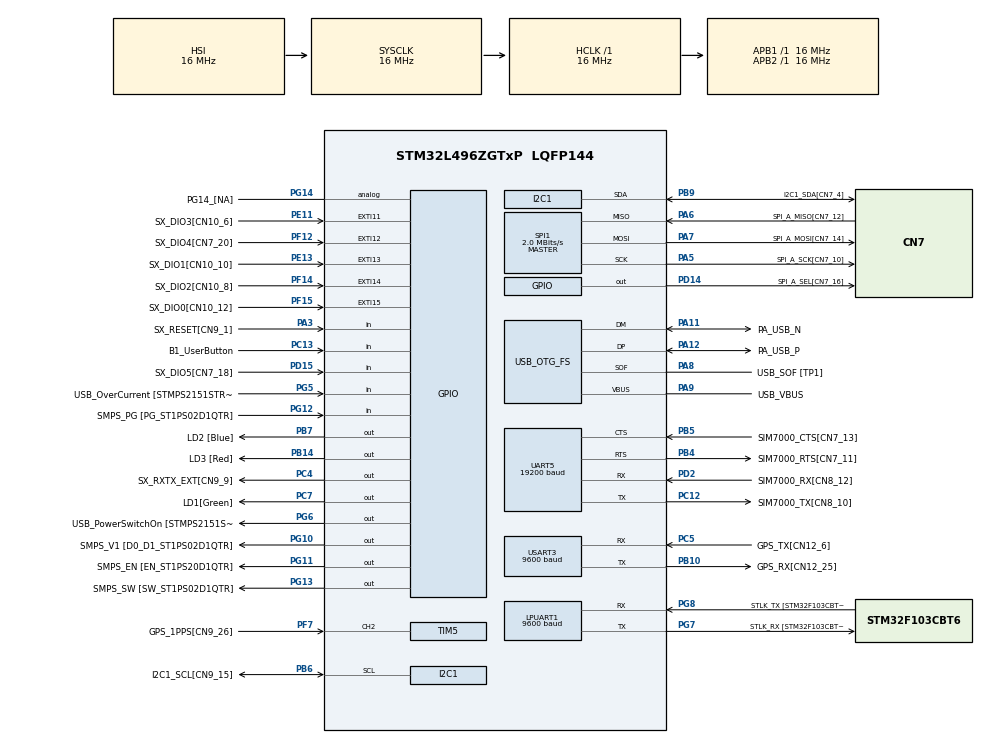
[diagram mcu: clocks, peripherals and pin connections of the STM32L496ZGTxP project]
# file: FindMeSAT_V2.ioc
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ADC1.Channel-0\#ChannelRegularConversion=ADC_CHANNEL_VREFINT
ADC1.Channel-1\#ChannelRegularConversion=ADC_CHANNEL_VBAT
ADC1.Channel-2\#ChannelRegularConversion=ADC_CHANNEL_TEMPSENSOR
ADC1.ClockPrescaler=ADC_CLOCK_ASYNC_DIV1
ADC1.ContinuousConvMode=DISABLE
ADC1.DMAContinuousRequests=DISABLE
ADC1.DiscontinuousConvMode=DISABLE
ADC1.EOCSelection=ADC_EOC_SEQ_CONV
ADC1.NbrOfConversion=3
ADC1.NbrOfConversionFlag=1
ADC1.OffsetNumber-0\#ChannelRegularConversion=ADC_OFFSET_NONE
ADC1.OffsetNumber-1\#ChannelRegularConversion=ADC_OFFSET_NONE
ADC1.OffsetNumber-2\#ChannelRegularConversion=ADC_OFFSET_NONE
ADC1.Overrun=ADC_OVR_DATA_OVERWRITTEN
ADC1.OversamplingMode=ENABLE
ADC1.Rank-0\#ChannelRegularConversion=1
ADC1.Rank-1\#ChannelRegularConversion=2
ADC1.Rank-2\#ChannelRegularConversion=3
ADC1.Ratio=ADC_OVERSAMPLING_RATIO_16
ADC1.RightBitShift=ADC_RIGHTBITSHIFT_NONE
ADC1.SamplingTime-0\#ChannelRegularConversion=ADC_SAMPLETIME_92CYCLES_5
ADC1.SamplingTime-1\#ChannelRegularConversion=ADC_SAMPLETIME_92CYCLES_5
ADC1.SamplingTime-2\#ChannelRegularConversion=ADC_SAMPLETIME_92CYCLES_5
ADC1.master=1
CRC.InputDataFormat=CRC_INPUTDATA_FORMAT_WORDS
Dma.ADC1.0.Direction=DMA_PERIPH_TO_MEMORY
Dma.ADC1.0.Instance=DMA1_Channel1
Dma.ADC1.0.MemDataAlignment=DMA_MDATAALIGN_HALFWORD
Dma.ADC1.0.MemInc=DMA_MINC_ENABLE
Dma.ADC1.0.Mode=DMA_CIRCULAR
Dma.ADC1.0.PeriphDataAlignment=DMA_PDATAALIGN_HALFWORD
Dma.ADC1.0.PeriphInc=DMA_PINC_DISABLE
Dma.ADC1.0.Priority=DMA_PRIORITY_LOW
Dma.LPUART_RX.8.Direction=DMA_PERIPH_TO_MEMORY
Dma.LPUART_RX.8.Instance=DMA2_Channel7
Dma.LPUART_RX.8.MemDataAlignment=DMA_MDATAALIGN_BYTE
Dma.LPUART_RX.8.MemInc=DMA_MINC_ENABLE
Dma.LPUART_RX.8.Mode=DMA_NORMAL
Dma.LPUART_RX.8.PeriphDataAlignment=DMA_PDATAALIGN_BYTE
Dma.LPUART_RX.8.PeriphInc=DMA_PINC_DISABLE
Dma.LPUART_RX.8.Priority=DMA_PRIORITY_HIGH
Dma.LPUART_TX.7.Direction=DMA_MEMORY_TO_PERIPH
Dma.LPUART_TX.7.Instance=DMA2_Channel6
Dma.LPUART_TX.7.MemDataAlignment=DMA_MDATAALIGN_BYTE
Dma.LPUART_TX.7.MemInc=DMA_MINC_ENABLE
Dma.LPUART_TX.7.Mode=DMA_NORMAL
Dma.LPUART_TX.7.PeriphDataAlignment=DMA_PDATAALIGN_BYTE
Dma.LPUART_TX.7.PeriphInc=DMA_PINC_DISABLE
Dma.LPUART_TX.7.Priority=DMA_PRIORITY_HIGH
Dma.Request0=ADC1
Dma.Request1=SPI1_TX
Dma.Request2=SPI1_RX
Dma.Request3=USART3_TX
Dma.Request4=USART3_RX
Dma.Request5=UART5_TX
Dma.Request6=UART5_RX
Dma.Request7=LPUART_TX
Dma.Request8=LPUART_RX
Dma.SPI1_RX.2.Direction=DMA_PERIPH_TO_MEMORY
Dma.SPI1_RX.2.Instance=DMA2_Channel3
Dma.SPI1_RX.2.MemDataAlignment=DMA_MDATAALIGN_BYTE
Dma.SPI1_RX.2.MemInc=DMA_MINC_ENABLE
Dma.SPI1_RX.2.Mode=DMA_NORMAL
Dma.SPI1_RX.2.PeriphDataAlignment=DMA_PDATAALIGN_BYTE
Dma.SPI1_RX.2.PeriphInc=DMA_PINC_DISABLE
Dma.SPI1_RX.2.Priority=DMA_PRIORITY_LOW
Dma.SPI1_TX.1.Direction=DMA_MEMORY_TO_PERIPH
Dma.SPI1_TX.1.Instance=DMA2_Channel4
Dma.SPI1_TX.1.MemDataAlignment=DMA_MDATAALIGN_BYTE
Dma.SPI1_TX.1.MemInc=DMA_MINC_ENABLE
Dma.SPI1_TX.1.Mode=DMA_NORMAL
Dma.SPI1_TX.1.PeriphDataAlignment=DMA_PDATAALIGN_BYTE
Dma.SPI1_TX.1.PeriphInc=DMA_PINC_DISABLE
Dma.SPI1_TX.1.Priority=DMA_PRIORITY_LOW
Dma.UART5_RX.6.Direction=DMA_PERIPH_TO_MEMORY
Dma.UART5_RX.6.Instance=DMA2_Channel2
Dma.UART5_RX.6.MemDataAlignment=DMA_MDATAALIGN_BYTE
Dma.UART5_RX.6.MemInc=DMA_MINC_ENABLE
Dma.UART5_RX.6.Mode=DMA_NORMAL
Dma.UART5_RX.6.PeriphDataAlignment=DMA_PDATAALIGN_BYTE
Dma.UART5_RX.6.PeriphInc=DMA_PINC_DISABLE
Dma.UART5_RX.6.Priority=DMA_PRIORITY_HIGH
Dma.UART5_TX.5.Direction=DMA_MEMORY_TO_PERIPH
Dma.UART5_TX.5.Instance=DMA2_Channel1
Dma.UART5_TX.5.MemDataAlignment=DMA_MDATAALIGN_BYTE
Dma.UART5_TX.5.MemInc=DMA_MINC_ENABLE
Dma.UART5_TX.5.Mode=DMA_NORMAL
Dma.UART5_TX.5.PeriphDataAlignment=DMA_PDATAALIGN_BYTE
Dma.UART5_TX.5.PeriphInc=DMA_PINC_DISABLE
Dma.UART5_TX.5.Priority=DMA_PRIORITY_HIGH
Dma.USART3_RX.4.Direction=DMA_PERIPH_TO_MEMORY
Dma.USART3_RX.4.Instance=DMA1_Channel3
Dma.USART3_RX.4.MemDataAlignment=DMA_MDATAALIGN_BYTE
Dma.USART3_RX.4.MemInc=DMA_MINC_ENABLE
Dma.USART3_RX.4.Mode=DMA_NORMAL
Dma.USART3_RX.4.PeriphDataAlignment=DMA_PDATAALIGN_BYTE
Dma.USART3_RX.4.PeriphInc=DMA_PINC_DISABLE
Dma.USART3_RX.4.Priority=DMA_PRIORITY_HIGH
Dma.USART3_TX.3.Direction=DMA_MEMORY_TO_PERIPH
Dma.USART3_TX.3.Instance=DMA1_Channel2
Dma.USART3_TX.3.MemDataAlignment=DMA_MDATAALIGN_BYTE
Dma.USART3_TX.3.MemInc=DMA_MINC_ENABLE
Dma.USART3_TX.3.Mode=DMA_NORMAL
Dma.USART3_TX.3.PeriphDataAlignment=DMA_PDATAALIGN_BYTE
Dma.USART3_TX.3.PeriphInc=DMA_PINC_DISABLE
Dma.USART3_TX.3.Priority=DMA_PRIORITY_HIGH
FREERTOS.BinarySemaphores01=usbToHostBinarySem,Dynamic,NULL
FREERTOS.HEAP_NUMBER=4
FREERTOS.INCLUDE_eTaskGetState=1
FREERTOS.INCLUDE_pcTaskGetTaskName=1
FREERTOS.INCLUDE_uxTaskGetStackHighWaterMark=1
FREERTOS.INCLUDE_vTaskCleanUpResources=1
FREERTOS.INCLUDE_vTaskDelayUntil=1
FREERTOS.INCLUDE_vTaskDelete=1
FREERTOS.INCLUDE_xEventGroupSetBitFromISR=1
FREERTOS.INCLUDE_xQueueGetMutexHolder=1
FREERTOS.INCLUDE_xSemaphoreGetMutexHolder=1
FREERTOS.INCLUDE_xTaskAbortDelay=1
FREERTOS.INCLUDE_xTaskGetCurrentTaskHandle=1
FREERTOS.INCLUDE_xTaskGetHandle=1
FREERTOS.INCLUDE_xTimerPendFunctionCall=1
FREERTOS.Mutexes01=gpscomCtxMutex,Dynamic,NULL;trackMeApplUpDataMutex,Dynamic,NULL;trackMeApplDnDataMutex,Dynamic,NULL
FREERTOS.Queues01=usbToHostQueue,512,uint8_t,0,Dynamic,NULL,NULL;usbFromHostQueue,32,uint8_t,0,Dynamic,NULL,NULL;loraInQueue,256,uint8_t,0,Dynamic,NULL,NULL;loraOutQueue,8,uint8_t,0,Dynamic,NULL,NULL;loraMacQueue,32,uint8_t,0,Dynamic,NULL,NULL;gpscomInQueue,64,uint8_t,0,Dynamic,NULL,NULL;gpscomOutQueue,8,uint8_t,0,Dynamic,NULL,NULL;sensorsOutQueue,32,uint8_t,0,Dynamic,NULL,NULL;sensorsInQueue,8,uint8_t,0,Dynamic,NULL,NULL;interOutQueue,256,uint8_t,0,Dynamic,NULL,NULL
FREERTOS.Tasks01=defaultTask,-2,128,StartDefaultTask,Default,NULL,Dynamic,NULL,NULL;usbToHostTask,1,128,StartUsbToHostTask,Default,NULL,Dynamic,NULL,NULL;usbFromHostTask,1,128,StartUsbFromHostTask,Default,NULL,Dynamic,NULL,NULL;controllerTask,0,1024,StartControllerTask,Default,NULL,Dynamic,NULL,NULL;interpreterTask,0,512,StartInterpreterTask,Default,NULL,Dynamic,NULL,NULL;loraTask,2,2048,StartLoraTask,Default,NULL,Dynamic,NULL,NULL;gpscomTask,3,1024,StartGpscomTask,Default,NULL,Dynamic,NULL,NULL;sensorsTask,1,128,StartSensorsTask,Default,NULL,Dynamic,NULL,NULL
FREERTOS.Timers01=controllerSendTimer,controllerSendTimerCallback,osTimerPeriodic,Default,NULL,Dynamic,NULL;gpscomtRXTimer,gpscomtRXTimerCallback,osTimerPeriodic,Default,NULL,Dynamic,NULL
FREERTOS.configCHECK_FOR_STACK_OVERFLOW=1
FREERTOS.configENABLE_BACKWARD_COMPATIBILITY=0
FREERTOS.configGENERATE_RUN_TIME_STATS=1
FREERTOS.configMINIMAL_STACK_SIZE=128
FREERTOS.configQUEUE_REGISTRY_SIZE=64
FREERTOS.configRECORD_STACK_HIGH_ADDRESS=1
FREERTOS.configTIMER_QUEUE_LENGTH=8
FREERTOS.configTOTAL_HEAP_SIZE=49152
FREERTOS.configUSE_APPLICATION_TASK_TAG=1
FREERTOS.configUSE_COUNTING_SEMAPHORES=1
FREERTOS.configUSE_IDLE_HOOK=1
FREERTOS.configUSE_MALLOC_FAILED_HOOK=1
FREERTOS.configUSE_STATS_FORMATTING_FUNCTIONS=1
FREERTOS.configUSE_TICKLESS_IDLE=0
FREERTOS.configUSE_TIMERS=1
FREERTOS.configUSE_TRACE_FACILITY=1
I2C1.I2C_Speed_Mode=I2C_Fast
I2C1.Timing=0x0010061A
LPUART1.AutoBaudRateEnableParam=UART_ADVFEATURE_AUTOBAUDRATE_DISABLE
LPUART1.BaudRate=9600
LPUART1.DMADisableonRxErrorParam=UART_ADVFEATURE_DMA_DISABLEONRXERROR
LPUART1.OneBitSampling=UART_ONE_BIT_SAMPLE_ENABLE
LPUART1.OverrunDisableParam=UART_ADVFEATURE_OVERRUN_DISABLE
LPUART1.WordLength=UART_WORDLENGTH_8B
Mcu.Family=STM32L4
Mcu.Name=STM32L496ZGTxP
Mcu.Package=LQFP144
NVIC.ADC1_2_IRQn=true\:5\:0\:false\:false\:true\:true\:true\:true
NVIC.DMA1_Channel1_IRQn=true\:5\:0\:false\:false\:true\:true\:false\:true
NVIC.DMA1_Channel2_IRQn=true\:5\:0\:false\:false\:true\:true\:false\:true
NVIC.DMA1_Channel3_IRQn=true\:5\:0\:false\:false\:true\:true\:false\:true
NVIC.DMA2_Channel1_IRQn=true\:5\:0\:false\:false\:true\:true\:false\:true
NVIC.DMA2_Channel2_IRQn=true\:5\:0\:false\:false\:true\:true\:false\:true
NVIC.DMA2_Channel3_IRQn=true\:5\:0\:false\:false\:true\:false\:false\:true
NVIC.DMA2_Channel4_IRQn=true\:5\:0\:false\:false\:true\:false\:false\:true
NVIC.DMA2_Channel6_IRQn=true\:5\:0\:false\:false\:true\:true\:false\:true
NVIC.DMA2_Channel7_IRQn=true\:5\:0\:false\:false\:true\:true\:false\:true
NVIC.EXTI15_10_IRQn=true\:5\:0\:false\:false\:true\:true\:true\:true
NVIC.I2C1_ER_IRQn=true\:5\:0\:false\:false\:true\:true\:true\:true
NVIC.I2C1_EV_IRQn=true\:5\:0\:false\:false\:true\:true\:true\:true
NVIC.OTG_FS_IRQn=true\:5\:0\:false\:false\:true\:true\:true\:true
NVIC.PriorityGroup=NVIC_PRIORITYGROUP_4
NVIC.RCC_IRQn=true\:5\:0\:false\:false\:true\:true\:true\:false
NVIC.RTC_Alarm_IRQn=true\:0\:0\:false\:false\:true\:false\:true\:true
NVIC.RTC_WKUP_IRQn=true\:0\:0\:false\:false\:true\:false\:true\:true
NVIC.SPI1_IRQn=true\:5\:0\:false\:false\:true\:true\:true\:true
NVIC.TIM2_IRQn=true\:0\:0\:false\:false\:true\:false\:false\:true
NVIC.TIM5_IRQn=true\:5\:0\:false\:false\:true\:true\:true\:true
NVIC.TimeBase=TIM2_IRQn
NVIC.TimeBaseIP=TIM2
NVIC.UART5_IRQn=true\:5\:0\:false\:false\:true\:true\:true\:true
NVIC.USART3_IRQn=true\:5\:0\:false\:false\:true\:true\:true\:true
PA10.GPIO_Label=USB_ID
PA10.GPIO_Speed=GPIO_SPEED_FREQ_LOW
PA10.Signal=USB_OTG_FS_ID
PA11.GPIO_Label=PA_USB_N
PA11.Mode=Device_Only
PA11.Signal=USB_OTG_FS_DM
PA12.GPIO_Label=PA_USB_P
PA12.Mode=Device_Only
PA12.Signal=USB_OTG_FS_DP
PA13\ (JTMS/SWDIO).GPIO_Label=TMS
PA13\ (JTMS/SWDIO).Mode=Trace_Asynchronous_SW
PA13\ (JTMS/SWDIO).Signal=SYS_JTMS-SWDIO
PA14\ (JTCK/SWCLK).GPIO_Label=TCK
PA14\ (JTCK/SWCLK).Mode=Trace_Asynchronous_SW
PA14\ (JTCK/SWCLK).Signal=SYS_JTCK-SWCLK
PA3.GPIO_Label=SX_RESET[CN9_1]
PA3.GPIO_PuPd=GPIO_PULLUP
PA3.Signal=GPIO_Input
PA5.GPIO_Label=SPI_A_SCK[CN7_10]
PA5.Mode=Full_Duplex_Master
PA5.Signal=SPI1_SCK
PA6.GPIO_Label=SPI_A_MISO[CN7_12]
PA6.GPIO_PuPd=GPIO_PULLDOWN
PA6.Mode=Full_Duplex_Master
PA6.Signal=SPI1_MISO
PA7.GPIO_Label=SPI_A_MOSI[CN7_14]
PA7.Mode=Full_Duplex_Master
PA7.Signal=SPI1_MOSI
PA8.GPIO_Label=USB_SOF [TP1]
PA8.Mode=Activate_SOF_FS
PA8.Signal=USB_OTG_FS_SOF
PA9.GPIO_Label=USB_VBUS
PA9.Mode=Activate_VBUS
PA9.Signal=USB_OTG_FS_VBUS
PB10.GPIO_Label=GPS_RX[CN12_25]
PB10.GPIO_PuPd=GPIO_NOPULL
PB10.GPIO_Speed=GPIO_SPEED_FREQ_MEDIUM
PB10.Mode=Asynchronous
PB10.Signal=USART3_TX
PB14.GPIO_Label=LD3 [Red]
PB14.Signal=GPIO_Output
PB3\ (JTDO/TRACESWO).GPIO_Label=SWO
PB3\ (JTDO/TRACESWO).Mode=Trace_Asynchronous_SW
PB3\ (JTDO/TRACESWO).Signal=SYS_JTDO-SWO
PB4\ (NJTRST).GPIO_Label=SIM7000_RTS[CN7_11]
PB4\ (NJTRST).GPIO_Speed=GPIO_SPEED_FREQ_MEDIUM
PB4\ (NJTRST).Mode=CTS_RTS
PB4\ (NJTRST).Signal=UART5_RTS
PB5.GPIO_Label=SIM7000_CTS[CN7_13]
PB5.GPIO_PuPd=GPIO_PULLUP
PB5.GPIO_Speed=GPIO_SPEED_FREQ_MEDIUM
PB5.Mode=CTS_RTS
PB5.Signal=UART5_CTS
PB6.GPIO_Label=I2C1_SCL[CN9_15]
PB6.Mode=I2C
PB6.Signal=I2C1_SCL
PB7.GPIO_Label=LD2 [Blue]
PB7.Signal=GPIO_Output
PB9.GPIO_Label=I2C1_SDA[CN7_4]
PB9.Mode=I2C
PB9.Signal=I2C1_SDA
PC12.GPIO_Label=SIM7000_TX[CN8_10]
PC12.GPIO_Speed=GPIO_SPEED_FREQ_MEDIUM
PC12.Mode=Asynchronous
PC12.Signal=UART5_TX
PC13.GPIO_Label=B1_UserButton
PC13.Signal=GPIO_Input
PC14-OSC32_IN\ (PC14).GPIO_Label=OSC32_IN
PC14-OSC32_IN\ (PC14).Mode=LSE-External-Oscillator
PC14-OSC32_IN\ (PC14).Signal=RCC_OSC32_IN
PC15-OSC32_OUT\ (PC15).GPIO_Label=OSC32_OUT
PC15-OSC32_OUT\ (PC15).Mode=LSE-External-Oscillator
PC15-OSC32_OUT\ (PC15).Signal=RCC_OSC32_OUT
PC4.GPIO_Label=SX_RXTX_EXT[CN9_9]
PC4.Signal=GPIO_Output
PC5.GPIO_Label=GPS_TX[CN12_6]
PC5.GPIO_PuPd=GPIO_PULLUP
PC5.GPIO_Speed=GPIO_SPEED_FREQ_MEDIUM
PC5.Mode=Asynchronous
PC5.Signal=USART3_RX
PC7.GPIO_Label=LD1[Green]
PC7.Signal=GPIO_Output
PD14.GPIO_Label=SPI_A_SEL[CN7_16]
PD14.GPIO_Speed=GPIO_SPEED_FREQ_HIGH
PD14.PinState=GPIO_PIN_SET
PD14.Signal=GPIO_Output
PD15.GPIO_Label=SX_DIO5[CN7_18]
PD15.GPIO_PuPd=GPIO_PULLDOWN
PD15.Signal=GPIO_Input
PD2.GPIO_Label=SIM7000_RX[CN8_12]
PD2.GPIO_PuPd=GPIO_PULLUP
PD2.GPIO_Speed=GPIO_SPEED_FREQ_MEDIUM
PD2.Mode=Asynchronous
PD2.Signal=UART5_RX
PE11.GPIO_Label=SX_DIO3[CN10_6]
PE11.GPIO_PuPd=GPIO_PULLDOWN
PE11.Signal=GPXTI11
PE13.GPIO_Label=SX_DIO1[CN10_10]
PE13.GPIO_PuPd=GPIO_PULLDOWN
PE13.Signal=GPXTI13
PF12.GPIO_Label=SX_DIO4[CN7_20]
PF12.GPIO_PuPd=GPIO_PULLDOWN
PF12.Signal=GPXTI12
PF14.GPIO_Label=SX_DIO2[CN10_8]
PF14.GPIO_PuPd=GPIO_PULLDOWN
PF14.Signal=GPXTI14
PF15.GPIO_Label=SX_DIO0[CN10_12]
PF15.GPIO_PuPd=GPIO_PULLDOWN
PF15.Signal=GPXTI15
PF7.GPIO_Label=GPS_1PPS[CN9_26]
PF7.GPIO_PuPd=GPIO_PULLDOWN
PF7.GPIO_Speed=GPIO_SPEED_FREQ_HIGH
PF7.Signal=S_TIM5_CH2
PG10.GPIO_Label=SMPS_V1 [D0_D1_ST1PS02D1QTR]
PG10.Signal=GPIO_Output
PG11.GPIO_Label=SMPS_EN [EN_ST1PS20D1QTR]
PG11.Signal=GPIO_Output
PG12.GPIO_Label=SMPS_PG [PG_ST1PS02D1QTR]
PG12.Signal=GPIO_Input
PG13.GPIO_Label=SMPS_SW [SW_ST1PS02D1QTR]
PG13.Signal=GPIO_Output
PG14.GPIO_Label=PG14_[NA]
PG14.Signal=GPIO_Analog
PG5.GPIO_Label=USB_OverCurrent [STMPS2151STR_FAULT]
PG5.Signal=GPIO_Input
PG6.GPIO_Label=USB_PowerSwitchOn [STMPS2151STR_EN]
PG6.Signal=GPIO_Output
PG7.GPIO_Label=STLK_RX [STM32F103CBT6_PA3]
PG7.GPIO_Speed=GPIO_SPEED_FREQ_MEDIUM
PG7.Mode=Asynchronous
PG7.Signal=LPUART1_TX
PG8.GPIO_Label=STLK_TX [STM32F103CBT6_PA2]
PG8.GPIO_PuPd=GPIO_PULLUP
PG8.GPIO_Speed=GPIO_SPEED_FREQ_MEDIUM
PG8.Mode=Asynchronous
PG8.Signal=LPUART1_RX
PH0-OSC_IN\ (PH0).GPIO_Label=MCO
PH0-OSC_IN\ (PH0).Mode=HSE-External-Clock-Source
PH0-OSC_IN\ (PH0).Signal=RCC_OSC_IN
PH1-OSC_OUT\ (PH1).Signal=RCC_OSC_OUT
ProjectManager.HeapSize=0x200
ProjectManager.StackSize=0x400
ProjectManager.TargetToolchain=TrueSTUDIO
RCC.48MHZClocksFreq_Value=24000000
RCC.ADCFreq_Value=8000000
RCC.AHBFreq_Value=16000000
RCC.APB1Freq_Value=16000000
RCC.APB1TimFreq_Value=16000000
RCC.APB2Freq_Value=16000000
RCC.APB2TimFreq_Value=16000000
RCC.CK48CLockSelection=RCC_USBCLKSOURCE_HSI48
RCC.CortexFreq_Value=16000000
RCC.HCLKFreq_Value=16000000
RCC.HSE_VALUE=0
RCC.HSI48_VALUE=48000000
RCC.HSI_VALUE=16000000
RCC.I2C1CLockSelection=RCC_I2C1CLKSOURCE_HSI
RCC.LPUART1CLockSelection=RCC_LPUART1CLKSOURCE_HSI
RCC.MSIAutoCalibration=ENABLED
RCC.MSIClockRange=RCC_MSIRANGE_0
RCC.MSI_VALUE=100000
RCC.PLLM=2
RCC.PLLMUL=RCC_PLL_MUL9
RCC.PLLN=20
RCC.PLLQ=RCC_PLLQ_DIV8
RCC.PLLSAI1Q=RCC_PLLQ_DIV8
RCC.PLLSAI1R=RCC_PLLR_DIV8
RCC.PLLSAI2R=RCC_PLLR_DIV8
RCC.PLLSourceVirtual=RCC_PLLSOURCE_HSI
RCC.PREFETCH_ENABLE=1
RCC.PRESCALERUSB=RCC_USBCLKSOURCE_PLL_DIV1_5
RCC.RTCClockSelection=RCC_RTCCLKSOURCE_LSE
RCC.SYSCLKFreq_VALUE=16000000
RCC.SYSCLKSource=RCC_SYSCLKSOURCE_HSI
RCC.SYSCLKSourceVirtual=RCC_SYSCLKSOURCE_PLLCLK
RCC.UART5CLockSelection=RCC_UART5CLKSOURCE_HSI
RCC.USART3CLockSelection=RCC_USART3CLKSOURCE_HSI
RCC.USBFreq_Value=48000000
RCC.VCOOutputFreq_Value=160000000
RTC.Alarm-Alarm\ A=RTC_ALARM_A
RTC.Format=RTC_FORMAT_BIN
RTC.Year=18
SH.S_TIM5_CH2.0=TIM5_CH2,Input_Capture2_from_TI2
SPI1.BaudRatePrescaler=SPI_BAUDRATEPRESCALER_8
SPI1.CLKPhase=SPI_PHASE_1EDGE
SPI1.CalculateBaudRate=2.0 MBits/s
SPI1.DataSize=SPI_DATASIZE_8BIT
SPI1.Direction=SPI_DIRECTION_2LINES
SPI1.Mode=SPI_MODE_MASTER
SPI1.NSSPMode=SPI_NSS_PULSE_DISABLE
SPI1.TIMode=SPI_TIMODE_DISABLE
SPI1.VirtualType=VM_MASTER
TIM5.AutoReloadPreload=TIM_AUTORELOAD_PRELOAD_DISABLE
TIM5.Channel-Input_Capture2_from_TI2=TIM_CHANNEL_2
TIM5.Period=16000000
TIM5.TIM_MasterOutputTrigger=TIM_TRGO_RESET
TIM5.TIM_MasterSlaveMode=TIM_MASTERSLAVEMODE_DISABLE
UART5.BaudRate=19200
UART5.DMADisableonRxErrorParam=UART_ADVFEATURE_DMA_DISABLEONRXERROR
UART5.OneBitSampling=UART_ONE_BIT_SAMPLE_ENABLE
UART5.OverrunDisableParam=UART_ADVFEATURE_OVERRUN_DISABLE
USART3.AutoBaudRateEnableParam=UART_ADVFEATURE_AUTOBAUDRATE_DISABLE
USART3.BaudRate=9600
USART3.DMADisableonRxErrorParam=ADVFEATURE_DMA_DISABLEONRXERROR
USART3.OneBitSampling=UART_ONE_BIT_SAMPLE_ENABLE
USART3.OverrunDisableParam=ADVFEATURE_OVERRUN_DISABLE
USART3.RxPinLevelInvertParam=ADVFEATURE_RXINV_DISABLE
USART3.VirtualMode-Asynchronous=VM_ASYNC
USART3.WordLength=WORDLENGTH_8B
USB_DEVICE.CLASS_NAME_FS=CDC
USB_DEVICE.MANUFACTURER_STRING=DF4IAH Solutions
USB_DEVICE.PRODUCT_STRING_CDC_FS=FindMeSAT V2
USB_DEVICE.USBD_LPM_ENABLED=1
USB_DEVICE.USBD_SELF_POWERED=0
USB_DEVICE.USBD_SUPPORT_USER_STRING=0
USB_DEVICE.VirtualMode=Cdc
USB_DEVICE.VirtualModeFS=Cdc_FS
USB_OTG_FS.VirtualMode=Device_Only
USB_OTG_FS.battery_charging_enable=DISABLE
USB_OTG_FS.lpm_enable=ENABLE
VP_ADC1_TempSens_Input.Mode=IN-TempSens
VP_ADC1_Vbat_Input.Mode=IN-Vbat
VP_ADC1_Vref_Input.Mode=IN-Vrefint
VP_CRC_VS_CRC.Mode=CRC_Activate
VP_FREERTOS_VS_CMSIS_V1.Mode=CMSIS_V1
VP_RTC_VS_RTC_Activate.Mode=RTC_Enabled
VP_RTC_VS_RTC_Alarm_A_Intern.Mode=Alarm A
VP_RTC_VS_RTC_Calendar.Mode=RTC_Calendar
VP_RTC_VS_RTC_WakeUp_intern.Mode=WakeUp
VP_SYS_VS_tim2.Mode=TIM2
VP_TIM5_VS_ClockSourceINT.Mode=Internal
VP_USB_DEVICE_VS_USB_DEVICE_CDC_FS.Mode=CDC_FS
board=NUCLEO-L496ZG-P

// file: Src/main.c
/* USER CODE BEGIN Header */
/**
  ******************************************************************************
  * @file           : main.c
  * @brief          : Main program body
  ******************************************************************************
  * This notice applies to any and all portions of this file
  * that are not between comment pairs USER CODE BEGIN and
  * USER CODE END. Other portions of this file, whether
  * inserted by the user or by software development tools
  * are owned by their respective copyright owners.
  *
  * Copyright (c) 2019 STMicroelectronics International N.V.
  * All rights reserved.
  *
  * Redistribution and use in source and binary forms, with or without
  * modification, are permitted, provided that the following conditions are met:
  *
  * 1. Redistribution of source code must retain the above copyright notice,
  *    this list of conditions and the following disclaimer.
  * 2. Redistributions in binary form must reproduce the above copyright notice,
  *    this list of conditions and the following disclaimer in the documentation
  *    and/or other materials provided with the distribution.
  * 3. Neither the name of STMicroelectronics nor the names of other
  *    contributors to this software may be used to endorse or promote products
  *    derived from this software without specific written permission.
  * 4. This software, including modifications and/or derivative works of this
  *    software, must execute solely and exclusively on microcontroller or
  *    microprocessor devices manufactured by or for STMicroelectronics.
  * 5. Redistribution and use of this software other than as permitted under
  *    this license is void and will automatically terminate your rights under
  *    this license.
  *
  * THIS SOFTWARE IS PROVIDED BY STMICROELECTRONICS AND CONTRIBUTORS "AS IS"
  * AND ANY EXPRESS, IMPLIED OR STATUTORY WARRANTIES, INCLUDING, BUT NOT
  * LIMITED TO, THE IMPLIED WARRANTIES OF MERCHANTABILITY, FITNESS FOR A
  * PARTICULAR PURPOSE AND NON-INFRINGEMENT OF THIRD PARTY INTELLECTUAL PROPERTY
  * RIGHTS ARE DISCLAIMED TO THE FULLEST EXTENT PERMITTED BY LAW. IN NO EVENT
  * SHALL STMICROELECTRONICS OR CONTRIBUTORS BE LIABLE FOR ANY DIRECT, INDIRECT,
  * INCIDENTAL, SPECIAL, EXEMPLARY, OR CONSEQUENTIAL DAMAGES (INCLUDING, BUT NOT
  * LIMITED TO, PROCUREMENT OF SUBSTITUTE GOODS OR SERVICES; LOSS OF USE, DATA,
  * OR PROFITS; OR BUSINESS INTERRUPTION) HOWEVER CAUSED AND ON ANY THEORY OF
  * LIABILITY, WHETHER IN CONTRACT, STRICT LIABILITY, OR TORT (INCLUDING
  * NEGLIGENCE OR OTHERWISE) ARISING IN ANY WAY OUT OF THE USE OF THIS SOFTWARE,
  * EVEN IF ADVISED OF THE POSSIBILITY OF SUCH DAMAGE.
  *
  ******************************************************************************
  */
/* USER CODE END Header */

#include "main.h"
#include "cmsis_os.h"
#include "adc.h"
#include "crc.h"
#include "dma.h"
#include "i2c.h"
#include "usart.h"
#include "rtc.h"
#include "spi.h"
#include "tim.h"
#include "usb_device.h"
#include "gpio.h"

/* USER CODE BEGIN Includes */
#include <stddef.h>
#include <sys/_stdint.h>
#include <stdio.h>
#include "stm32l4xx_nucleo_144.h"
#include "stm32l4xx_hal.h"
#include "controller.h"

#ifndef portAIRCR_REG
#define portAIRCR_REG                       ( * ( ( volatile uint32_t * ) 0xE000ED0C ) )
#define SCB_AIRCR_SYSRESETREQ               0x05FA0002
#endif

#ifndef SCB_AIRCR_SYSRESETREQ_Msk
#define SCB_AIRCR_SYSRESETREQ_Pos           2U
#define SCB_AIRCR_SYSRESETREQ_Msk           (1UL << SCB_AIRCR_SYSRESETREQ_Pos)
#endif

/* USER CODE END Includes */

/* USER CODE BEGIN PV */
/* Private variables ---------------------------------------------------------*/
extern TIM_HandleTypeDef    htim3;
extern TIM_HandleTypeDef    htim4;
extern TIM_HandleTypeDef    htim5;

extern EventGroupHandle_t   controllerEventGroupHandle;

static GPIO_InitTypeDef     GPIO_InitStruct;

#if 0
volatile ENABLE_MASK_t      g_enableMsk                       = ENABLE_MASK__LORA_BARE      |                               ENABLE_MASK__GPS_DATA | ENABLE_MASK__GPS_1PPS;
#elif 0
volatile ENABLE_MASK_t      g_enableMsk                       =                               ENABLE_MASK__LORAWAN_DEVICE | ENABLE_MASK__GPS_DATA | ENABLE_MASK__GPS_1PPS;
#else
volatile ENABLE_MASK_t      g_enableMsk                       = ENABLE_MASK__LORA_BARE      | ENABLE_MASK__LORAWAN_DEVICE | ENABLE_MASK__GPS_DATA | ENABLE_MASK__GPS_1PPS;
#endif
volatile MON_MASK_t         g_monMsk                          = MON_MASK__LORA;

volatile uint64_t	          g_timer_us                        = 0ULL;
volatile uint64_t	          g_timerStart_us                   = 0ULL;
volatile uint64_t           g_realTime_Boot                   = 0ULL;

volatile uint32_t           g_unx_s                           = 0UL;                            // Current    time - since UN*X epoch in  s
volatile uint32_t           g_unx_s_next                      = 0UL;
volatile uint32_t           g_pps_us                          = 0UL;                            // 1PPS event time - 0 .. 999999 us

volatile uint32_t           g_TIM5_CCR2                       = 0UL;
volatile uint32_t           g_TIM5_ofs                        = 0UL;

/* USER CODE END PV */

void SystemClock_Config(void);
void MX_FREERTOS_Init(void);
/* USER CODE BEGIN PFP */
/* Private function prototypes -----------------------------------------------*/
void SystemClock_16MHz(void);
void SMPS_Init(void);

/* USER CODE END PFP */

/* USER CODE BEGIN 0 */

void mainDefaultTaskInit(void)
{
  /* -1- Enable GPIO Clock (to be able to program the configuration registers) */
  LED1_GPIO_CLK_ENABLE();  // Green
  LED2_GPIO_CLK_ENABLE();  // Blue
  LED3_GPIO_CLK_ENABLE();  // Red

  /* -2- Configure IO in output push-pull mode to drive external LEDs */
  GPIO_InitStruct.Mode = GPIO_MODE_OUTPUT_PP;
  GPIO_InitStruct.Pull = GPIO_PULLUP;
  GPIO_InitStruct.Speed = GPIO_SPEED_FREQ_VERY_HIGH;

  GPIO_InitStruct.Pin = LED1_PIN;
  HAL_GPIO_Init(LED1_GPIO_PORT, &GPIO_InitStruct);
  GPIO_InitStruct.Pin = LED2_PIN;
  HAL_GPIO_Init(LED2_GPIO_PORT, &GPIO_InitStruct);
  GPIO_InitStruct.Pin = LED3_PIN;
  HAL_GPIO_Init(LED3_GPIO_PORT, &GPIO_InitStruct);

  /* Enable 1PPS time capture on TIM5/Channel2 */
  HAL_TIM_IC_Start_IT(&htim5, TIM_CHANNEL_2);

  /* Enable external SMPS for Vdd12 */
  SMPS_Init();
}

void mainDefaultTaskLoop(void)
{
#if 0
  unsigned char buf[32] = { 0 };
  strcpy((char*) buf, "+\r\n");

  snprintf((char*) (buf + 1), sizeof(buf), " %010ld\r\n", getRunTimeCounterValue());
  usbToHost(buf, strlen((char*) buf));
#endif

  osDelay(60 * 1000);
}

/* USER CODE END 0 */

int main(void)
{
  /* USER CODE BEGIN 1 */

  /* Check if ARM core is already in reset state */
  if (!(RCC->CSR & 0xff000000UL)) {
    /* Disable SMPS */
    HAL_GPIO_WritePin(PORT_SMPS, PIN_SMPS_SWITCH_ENABLE, GPIO_PIN_RESET);
    __asm volatile( "ISB" );
    HAL_GPIO_WritePin(PORT_SMPS, PIN_SMPS_ENABLE, GPIO_PIN_RESET);

    /* ARM software reset to be done */
    SystemResetbyARMcore();
  }
  __HAL_RCC_CLEAR_RESET_FLAGS();

  /* USER CODE END 1 */

  /* MCU Configuration--------------------------------------------------------*/

  /* Reset of all peripherals, Initializes the Flash interface and the Systick. */
  HAL_Init();

  /* USER CODE BEGIN Init */

  /* For frequencies > 24 MHz switch to SCALE1 */
  HAL_PWREx_ControlVoltageScaling(PWR_REGULATOR_VOLTAGE_SCALE1);

  /* USER CODE END Init */

  /* Configure the system clock */
  SystemClock_Config();

  /* Initialize all configured peripherals */
  MX_GPIO_Init();
  MX_DMA_Init();
  MX_LPUART1_UART_Init();
  MX_TIM5_Init();
  MX_SPI1_Init();
  MX_UART5_Init();
  MX_I2C1_Init();
  MX_RTC_Init();
  MX_ADC1_Init();
  MX_CRC_Init();
  MX_USART3_UART_Init();
  /* USER CODE BEGIN 2 */

  /* Speed down to 16 MHz */
  SystemClock_16MHz();

  /* USER CODE END 2 */

  /* Call init function for freertos objects (in freertos.c) */
  MX_FREERTOS_Init();

  /* Start scheduler */
  osKernelStart();

  /* We should never get here as control is now taken by the scheduler */

  /* Infinite loop */
  /* USER CODE BEGIN WHILE */

  /* Something got wrong! */
  Error_Handler();

  while (1)
  {
    /* USER CODE END WHILE */

  }
}

void SystemClock_Config(void)
{
  RCC_OscInitTypeDef RCC_OscInitStruct = {0};
  RCC_ClkInitTypeDef RCC_ClkInitStruct = {0};
  RCC_PeriphCLKInitTypeDef PeriphClkInit = {0};

  /** Configure LSE Drive Capability
  */
  HAL_PWR_EnableBkUpAccess();
  __HAL_RCC_LSEDRIVE_CONFIG(RCC_LSEDRIVE_LOW);
  /** Initializes the CPU, AHB and APB busses clocks
  */
  RCC_OscInitStruct.OscillatorType = RCC_OSCILLATORTYPE_HSI48|RCC_OSCILLATORTYPE_HSI
                              |RCC_OSCILLATORTYPE_LSE;
  RCC_OscInitStruct.LSEState = RCC_LSE_ON;
  RCC_OscInitStruct.HSIState = RCC_HSI_ON;
  RCC_OscInitStruct.HSI48State = RCC_HSI48_ON;
  RCC_OscInitStruct.HSICalibrationValue = RCC_HSICALIBRATION_DEFAULT;
  RCC_OscInitStruct.PLL.PLLState = RCC_PLL_NONE;
  if (HAL_RCC_OscConfig(&RCC_OscInitStruct) != HAL_OK)
  {
    Error_Handler();
  }
  /** Initializes the CPU, AHB and APB busses clocks
  */
  RCC_ClkInitStruct.ClockType = RCC_CLOCKTYPE_HCLK|RCC_CLOCKTYPE_SYSCLK
                              |RCC_CLOCKTYPE_PCLK1|RCC_CLOCKTYPE_PCLK2;
  RCC_ClkInitStruct.SYSCLKSource = RCC_SYSCLKSOURCE_HSI;
  RCC_ClkInitStruct.AHBCLKDivider = RCC_SYSCLK_DIV1;
  RCC_ClkInitStruct.APB1CLKDivider = RCC_HCLK_DIV1;
  RCC_ClkInitStruct.APB2CLKDivider = RCC_HCLK_DIV1;

  if (HAL_RCC_ClockConfig(&RCC_ClkInitStruct, FLASH_LATENCY_0) != HAL_OK)
  {
    Error_Handler();
  }
  PeriphClkInit.PeriphClockSelection = RCC_PERIPHCLK_RTC|RCC_PERIPHCLK_USART3
                              |RCC_PERIPHCLK_UART5|RCC_PERIPHCLK_LPUART1
                              |RCC_PERIPHCLK_I2C1|RCC_PERIPHCLK_USB
                              |RCC_PERIPHCLK_ADC;
  PeriphClkInit.Usart3ClockSelection = RCC_USART3CLKSOURCE_HSI;
  PeriphClkInit.Uart5ClockSelection = RCC_UART5CLKSOURCE_HSI;
  PeriphClkInit.Lpuart1ClockSelection = RCC_LPUART1CLKSOURCE_HSI;
  PeriphClkInit.I2c1ClockSelection = RCC_I2C1CLKSOURCE_HSI;
  PeriphClkInit.AdcClockSelection = RCC_ADCCLKSOURCE_PLLSAI1;
  PeriphClkInit.RTCClockSelection = RCC_RTCCLKSOURCE_LSE;
  PeriphClkInit.UsbClockSelection = RCC_USBCLKSOURCE_HSI48;
  PeriphClkInit.PLLSAI1.PLLSAI1Source = RCC_PLLSOURCE_HSI;
  PeriphClkInit.PLLSAI1.PLLSAI1M = 2;
  PeriphClkInit.PLLSAI1.PLLSAI1N = 8;
  PeriphClkInit.PLLSAI1.PLLSAI1P = RCC_PLLP_DIV2;
  PeriphClkInit.PLLSAI1.PLLSAI1Q = RCC_PLLQ_DIV8;
  PeriphClkInit.PLLSAI1.PLLSAI1R = RCC_PLLR_DIV8;
  PeriphClkInit.PLLSAI1.PLLSAI1ClockOut = RCC_PLLSAI1_ADC1CLK;
  if (HAL_RCCEx_PeriphCLKConfig(&PeriphClkInit) != HAL_OK)
  {
    Error_Handler();
  }
  /** Configure the main internal regulator output voltage
  */
  if (HAL_PWREx_ControlVoltageScaling(PWR_REGULATOR_VOLTAGE_SCALE1) != HAL_OK)
  {
    Error_Handler();
  }
  /** Enable MSI Auto calibration
  */
  HAL_RCCEx_EnableMSIPLLMode();
}

/* USER CODE BEGIN 4 */
void SystemClock_16MHz(void)
{
  RCC_OscInitTypeDef RCC_OscInitStruct;
  RCC_ClkInitTypeDef RCC_ClkInitStruct;
  RCC_PeriphCLKInitTypeDef PeriphClkInit;

    /**Configure LSE Drive Capability
    */
  HAL_PWR_EnableBkUpAccess();

  __HAL_RCC_LSEDRIVE_CONFIG(RCC_LSEDRIVE_LOW);

    /**Initializes the CPU, AHB and APB busses clocks
    */
  RCC_OscInitStruct.OscillatorType = RCC_OSCILLATORTYPE_HSI48|RCC_OSCILLATORTYPE_HSI
                              |RCC_OSCILLATORTYPE_LSE;
  RCC_OscInitStruct.LSEState = RCC_LSE_ON;
  RCC_OscInitStruct.HSIState = RCC_HSI_ON;
  RCC_OscInitStruct.HSI48State = RCC_HSI48_ON;
  RCC_OscInitStruct.HSICalibrationValue = 64;
  RCC_OscInitStruct.PLL.PLLState = RCC_PLL_NONE;
  if (HAL_RCC_OscConfig(&RCC_OscInitStruct) != HAL_OK)
  {
    Error_Handler();
  }

    /**Initializes the CPU, AHB and APB busses clocks
    */
  RCC_ClkInitStruct.ClockType = RCC_CLOCKTYPE_HCLK|RCC_CLOCKTYPE_SYSCLK
                              |RCC_CLOCKTYPE_PCLK1|RCC_CLOCKTYPE_PCLK2;
  RCC_ClkInitStruct.SYSCLKSource = RCC_SYSCLKSOURCE_HSI;
  RCC_ClkInitStruct.AHBCLKDivider = RCC_SYSCLK_DIV1;
  RCC_ClkInitStruct.APB1CLKDivider = RCC_HCLK_DIV1;
  RCC_ClkInitStruct.APB2CLKDivider = RCC_HCLK_DIV1;

  if (HAL_RCC_ClockConfig(&RCC_ClkInitStruct, FLASH_LATENCY_0) != HAL_OK)
  {
    Error_Handler();
  }

  PeriphClkInit.PeriphClockSelection = RCC_PERIPHCLK_RTC|RCC_PERIPHCLK_UART5
                              |RCC_PERIPHCLK_LPUART1|RCC_PERIPHCLK_I2C1
                              |RCC_PERIPHCLK_USB;
  PeriphClkInit.Uart5ClockSelection = RCC_UART5CLKSOURCE_HSI;
  PeriphClkInit.Lpuart1ClockSelection = RCC_LPUART1CLKSOURCE_HSI;
  PeriphClkInit.I2c1ClockSelection = RCC_I2C1CLKSOURCE_HSI;
  PeriphClkInit.RTCClockSelection = RCC_RTCCLKSOURCE_LSE;
  PeriphClkInit.UsbClockSelection = RCC_USBCLKSOURCE_HSI48;
  if (HAL_RCCEx_PeriphCLKConfig(&PeriphClkInit) != HAL_OK)
  {
    Error_Handler();
  }

    /**Configure the main internal regulator output voltage
    */
  if (HAL_PWREx_ControlVoltageScaling(PWR_REGULATOR_VOLTAGE_SCALE1) != HAL_OK)
  {
    Error_Handler();
  }

    /**Configure the Systick interrupt time
    */
  HAL_SYSTICK_Config(HAL_RCC_GetHCLKFreq()/1000);

    /**Configure the Systick
    */
  HAL_SYSTICK_CLKSourceConfig(SYSTICK_CLKSOURCE_HCLK);

    /**Enable MSI Auto calibration
    */
  HAL_RCCEx_EnableMSIPLLMode();

  /* SysTick_IRQn interrupt configuration */
  HAL_NVIC_SetPriority(SysTick_IRQn, 15, 0);
}

void SMPS_Init(void)
{
  uint32_t SMPS_status_local = 0;

  /* Enable clock to the destinations needed */
  PWR_AND_CLK_SMPS();

  /* Reduce to max. speed (24 MHz) of Range2 */
  SystemClock_16MHz();
  HAL_PWREx_ControlVoltageScaling(PWR_REGULATOR_VOLTAGE_SCALE2);

  /* Prepare port pins */
  SMPS_status_local = BSP_SMPS_Init(0);
  if (SMPS_status_local != SMPS_OK) {
    Error_Handler();
  }

  /* Enable SMPS switcher and check for Power Good after 10ms */
  SMPS_status_local = BSP_SMPS_Enable(10, 1);
  if (SMPS_status_local != SMPS_OK) {
    Error_Handler();
  }

  /* Close switch between SMPS switcher and Vdd12 - (PG being checked again)*/
  SMPS_status_local = BSP_SMPS_Supply_Enable(0, 1);
  if (SMPS_status_local != SMPS_OK) {
    Error_Handler();
  }

  /* Go up to target speed */
  SystemClock_Config();

  /* Keep the internal regulator below of the SMPS voltage */
  HAL_PWREx_ControlVoltageScaling(PWR_REGULATOR_VOLTAGE_SCALE2);
}

/* Used by the run-time stats */
void configureTimerForRunTimeStats(void)
{
  getRunTimeCounterValue();

  /* Interrupt disabled block */
  {
    taskDISABLE_INTERRUPTS();
    g_timerStart_us = g_timer_us;
    taskENABLE_INTERRUPTS();
  }
}

/* Used by the run-time stats */
unsigned long getRunTimeCounterValue(void)
{
  uint64_t l_timerStart_us;
  uint64_t timer_us = HAL_GetTick() & 0x003fffffUL;  // avoid overflows
  timer_us *= 1000UL;
  timer_us += TIM2->CNT;

  /* Interrupt disabled block */
  {
    taskDISABLE_INTERRUPTS();
    g_timer_us      = timer_us;
    l_timerStart_us = g_timerStart_us;
    taskENABLE_INTERRUPTS();
  }

  return (unsigned long) (timer_us - l_timerStart_us);
}

/* Adjusts the global timers TIM4 / TIM3 / TIM5 with UNIX time (ï¿½s) */
int32_t setRealTime(uint64_t unixTime_us)
{
  uint16_t  l_TIM4_CNT;
  uint16_t  l_TIM3_CNT;
  uint32_t  l_TIM5_CNT;
  uint64_t  l_realTime_Outdated;
  uint64_t  l_realTime_Now;
  int64_t   l_diff_last;

  /* Interrupt disabled block */
  {
    taskDISABLE_INTERRUPTS();
    l_TIM5_CNT = TIM5->CNT;
    l_TIM3_CNT = TIM3->CNT;
    l_TIM4_CNT = TIM4->CNT;
    taskENABLE_INTERRUPTS();
  }

  /* Calculate the timestamp of the outdated timer */
  l_realTime_Outdated  = (uint64_t)l_TIM4_CNT << 48U;
  l_realTime_Outdated |= (uint64_t)l_TIM3_CNT << 32U;
  l_realTime_Outdated += (uint64_t) (l_TIM5_CNT / (HSI_VALUE / 1e7));

  /* Calculate the last offset */
  l_diff_last = l_realTime_Outdated - unixTime_us;

  /* Calculate the new boot timestamp */
  l_realTime_Now  = l_realTime_Outdated;
  l_realTime_Now -= l_diff_last;

  /* Interrupt disabled block */
  {
    taskDISABLE_INTERRUPTS();
    TIM5->CNT = l_TIM5_CNT;
    TIM3->CNT = l_TIM3_CNT;
    TIM4->CNT = l_TIM4_CNT;
    taskENABLE_INTERRUPTS();
  }

  return (int32_t) l_diff_last;
}

/* Returns the UNIX time in ï¿½s */
uint64_t getRealTime(void)
{
  uint16_t  l_TIM4_CNT;
  uint16_t  l_TIM3_CNT;
  uint32_t  l_TIM5_CNT;
  uint64_t  l_realTime_Now;

  /* Interrupt disabled block */
  {
    taskDISABLE_INTERRUPTS();
    l_TIM5_CNT = TIM5->CNT;
    l_TIM3_CNT = TIM3->CNT;
    l_TIM4_CNT = TIM4->CNT;
    taskENABLE_INTERRUPTS();
  }

  /* Calculate the timestamp of now */
  l_realTime_Now  = (uint64_t)l_TIM4_CNT << 48U;
  l_realTime_Now |= (uint64_t)l_TIM3_CNT << 32U;
  l_realTime_Now += (uint64_t) (l_TIM5_CNT / (HSI_VALUE / 1e7));

  return l_realTime_Now;
}

void SystemResetbyARMcore(void)
{
  /* Switch off SMPS first */
  HAL_PWREx_ControlVoltageScaling(PWR_REGULATOR_VOLTAGE_SCALE1);
  HAL_GPIO_WritePin(PORT_SMPS, PIN_SMPS_SWITCH_ENABLE, GPIO_PIN_RESET);
  __asm volatile( "ISB" );
  HAL_GPIO_WritePin(PORT_SMPS, PIN_SMPS_ENABLE, GPIO_PIN_RESET);

  /* Set SW reset bit */
  SCB->AIRCR = 0x05FA0000UL | SCB_AIRCR_SYSRESETREQ_Msk;
}

void vAssertCalled(const char *pcFile, uint32_t ulLine)
{
  /* Inside this function, pcFile holds the name of the source file that contains
  the line that detected the error, and ulLine holds the line number in the source
  file. The pcFile and ulLine values can be printed out, or otherwise recorded,
  before the following infinite loop is entered. */
  //RecordErrorInformationHere( pcFile, ulLine );
  /* Disable interrupts so the tick interrupt stops executing, then sit in a loop
  so execution does not move past the line that failed the assertion. */
  taskDISABLE_INTERRUPTS();
  for(;;)
  {
      __asm volatile( "nop" );
  }
}

void vApplicationStackOverflowHook(TaskHandle_t xTask, signed char *pcTaskName)
{
   /* Run time stack overflow checking is performed if
   configCHECK_FOR_STACK_OVERFLOW is defined to 1 or 2. This hook function is
   called if a stack overflow is detected. */
   vAssertCalled(__FILE__, __LINE__);
}

void vApplicationMallocFailedHook(void)
{
   /* vApplicationMallocFailedHook() will only be called if
   configUSE_MALLOC_FAILED_HOOK is set to 1 in FreeRTOSConfig.h. It is a hook
   function that will get called if a call to pvPortMalloc() fails.
   pvPortMalloc() is called internally by the kernel whenever a task, queue,
   timer or semaphore is created. It is also called by various parts of the
   demo application. If heap_1.c or heap_2.c are used, then the size of the
   heap available to pvPortMalloc() is defined by configTOTAL_HEAP_SIZE in
   FreeRTOSConfig.h, and the xPortGetFreeHeapSize() API function can be used
   to query the size of free heap space that remains (although it does not
   provide information on how the remaining heap might be fragmented). */
  vAssertCalled(__FILE__, __LINE__);
}

//#define LED_IDLE_DEBUG
void  vApplicationIdleHook(void)
{
  /* vApplicationIdleHook() will only be called if configUSE_IDLE_HOOK is set
  to 1 in FreeRTOSConfig.h. It will be called on each iteration of the idle
  task. It is essential that code added to this hook function never attempts
  to block in any way (for example, call xQueueReceive() with a block time
  specified, or call vTaskDelay()). If the application makes use of the
  vTaskDelete() API function (as this demo application does) then it is also
  important that vApplicationIdleHook() is permitted to return to its calling
  function, because it is the responsibility of the idle task to clean up
  memory allocated by the kernel to any task that has since been deleted. */
  /* TODO:
   * 1) Reduce 80 MHz  to  2 MHz
   * 2)  go to LPRun  (SMPS 2 High (-->  MR range 1) --> MR range 2 --> LPR
   * 3)  Go to LPSleep
   *
   * WAKEUP
   * 1)  In LPRun go to 80 MHz (LPR --> MR range 2 (--> MR range 1) --> SMPS 2 High)
   * 2)  Increase 2 MHz to 80 MHz
   */
#ifdef LED_IDLE_DEBUG
  HAL_GPIO_WritePin(LED2_GPIO_PORT, LED2_PIN, GPIO_PIN_SET);                                    // Blue on
#endif

  /* Enter sleep mode */
  __asm volatile( "WFI" );

#ifdef LED_IDLE_DEBUG
  HAL_GPIO_WritePin(LED2_GPIO_PORT, LED2_PIN, GPIO_PIN_RESET);                                  // Blue off
#endif
  /* Increase clock frequency to 80 MHz */
  // TODO: TBD
}

void mainCalc_Float2Int(float in, uint32_t* out_i, uint16_t* out_p1000)
{
  if (in < 0) {
    in = -in;
  }

  *out_i      = (uint32_t) in;
  *out_p1000  = (uint16_t) (((uint32_t) (in * 1000.f)) % 1000);
}

/**
  * @brief  Input Capture callback in non-blocking mode
  * @param  htim TIM IC handle
  * @retval None
  */
void HAL_TIM_IC_CaptureCallback(TIM_HandleTypeDef *htim)
{
  if ((htim->Instance  == htim5.Instance           ) &&
      (htim->Channel   == HAL_TIM_ACTIVE_CHANNEL_2)) {

    /* Fetch and Stash - BEGIN */
    taskDISABLE_INTERRUPTS();

    const uint32_t l_TIM5_CNT   = htim->Instance->CNT;
    htim->Instance->CNT         = (uint32_t) ((l_TIM5_CNT + g_TIM5_ofs) % Tim5_reloadValue);
    g_TIM5_ofs                  = 0UL;

    const uint32_t l_TIM5_CCR2  = htim->Instance->CCR2;
    g_TIM5_CCR2                 = l_TIM5_CCR2;

    g_unx_s                     = g_unx_s_next;
#ifdef IS_N_X_1MHZ
    g_pps_us                    = (uint32_t) (l_TIM5_CCR2 / (Tim5_reloadValue / 1000000UL));
#else
    g_pps_us                    = (uint32_t) (l_TIM5_CCR2 / (Tim5_reloadValue / 1e6));
#endif

    taskENABLE_INTERRUPTS();
    /* Fetch and Stash - END */

    /* Show 1PPS by reversing the red LED */
    HAL_GPIO_TogglePin(LED3_GPIO_PORT, LED3_PIN);                                               // Red toggling

    /* Message to controller */
    {
      BaseType_t  higherPriorityTaskWOken = 0UL;

      if (controllerEventGroupHandle) {
        xEventGroupSetBitsFromISR(controllerEventGroupHandle, Controller_EGW__TIM_PPS, &higherPriorityTaskWOken);
      }
    }
  }
}

/* USER CODE END 4 */

void HAL_TIM_PeriodElapsedCallback(TIM_HandleTypeDef *htim)
{
  if (htim->Instance == TIM2) {
    HAL_IncTick();
  }
  /* USER CODE BEGIN Callback 1 */

  if (htim->Instance == TIM5) {
    /* Seconds counter */
    ++g_unx_s;
  }
  /* USER CODE END Callback 1 */
}

void Error_Handler(void)
{
  /* USER CODE BEGIN Error_Handler_Debug */
  /* User can add his own implementation to report the HAL error return state */
  vAssertCalled(__FILE__, __LINE__);
  /* USER CODE END Error_Handler_Debug */
}

#ifdef  USE_FULL_ASSERT
/**
  * @brief  Reports the name of the source file and the source line number
  *         where the assert_param error has occurred.
  * @param  file: pointer to the source file name
  * @param  line: assert_param error line source number
  * @retval None
  */
void assert_failed(char *file, uint32_t line)
{
  /* USER CODE BEGIN 6 */
  vAssertCalled((char *) file, line);
  /* USER CODE END 6 */
}
#endif /* USE_FULL_ASSERT */

/************************ (C) COPYRIGHT STMicroelectronics *****END OF FILE****/

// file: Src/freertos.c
/* USER CODE BEGIN Header */
/**
  ******************************************************************************
  * File Name          : freertos.c
  * Description        : Code for freertos applications
  ******************************************************************************
  * This notice applies to any and all portions of this file
  * that are not between comment pairs USER CODE BEGIN and
  * USER CODE END. Other portions of this file, whether
  * inserted by the user or by software development tools
  * are owned by their respective copyright owners.
  *
  * Copyright (c) 2019 STMicroelectronics International N.V.
  * All rights reserved.
  *
  * Redistribution and use in source and binary forms, with or without
  * modification, are permitted, provided that the following conditions are met:
  *
  * 1. Redistribution of source code must retain the above copyright notice,
  *    this list of conditions and the following disclaimer.
  * 2. Redistributions in binary form must reproduce the above copyright notice,
  *    this list of conditions and the following disclaimer in the documentation
  *    and/or other materials provided with the distribution.
  * 3. Neither the name of STMicroelectronics nor the names of other
  *    contributors to this software may be used to endorse or promote products
  *    derived from this software without specific written permission.
  * 4. This software, including modifications and/or derivative works of this
  *    software, must execute solely and exclusively on microcontroller or
  *    microprocessor devices manufactured by or for STMicroelectronics.
  * 5. Redistribution and use of this software other than as permitted under
  *    this license is void and will automatically terminate your rights under
  *    this license.
  *
  * THIS SOFTWARE IS PROVIDED BY STMICROELECTRONICS AND CONTRIBUTORS "AS IS"
  * AND ANY EXPRESS, IMPLIED OR STATUTORY WARRANTIES, INCLUDING, BUT NOT
  * LIMITED TO, THE IMPLIED WARRANTIES OF MERCHANTABILITY, FITNESS FOR A
  * PARTICULAR PURPOSE AND NON-INFRINGEMENT OF THIRD PARTY INTELLECTUAL PROPERTY
  * RIGHTS ARE DISCLAIMED TO THE FULLEST EXTENT PERMITTED BY LAW. IN NO EVENT
  * SHALL STMICROELECTRONICS OR CONTRIBUTORS BE LIABLE FOR ANY DIRECT, INDIRECT,
  * INCIDENTAL, SPECIAL, EXEMPLARY, OR CONSEQUENTIAL DAMAGES (INCLUDING, BUT NOT
  * LIMITED TO, PROCUREMENT OF SUBSTITUTE GOODS OR SERVICES; LOSS OF USE, DATA,
  * OR PROFITS; OR BUSINESS INTERRUPTION) HOWEVER CAUSED AND ON ANY THEORY OF
  * LIABILITY, WHETHER IN CONTRACT, STRICT LIABILITY, OR TORT (INCLUDING
  * NEGLIGENCE OR OTHERWISE) ARISING IN ANY WAY OUT OF THE USE OF THIS SOFTWARE,
  * EVEN IF ADVISED OF THE POSSIBILITY OF SUCH DAMAGE.
  *
  ******************************************************************************
  */
/* USER CODE END Header */

#include "FreeRTOS.h"
#include "task.h"
#include "main.h"
#include "cmsis_os.h"

/* USER CODE BEGIN Includes */
#include "stm32l4xx_nucleo_144.h"
#include "stm32l4xx_hal.h"
#include "controller.h"
#include "interpreter.h"
#include "usb.h"
#include "LoRaWAN.h"
#include "gpsCom.h"
#include "sensors.h"

/* USER CODE END Includes */

/* USER CODE BEGIN Variables */
extern uint8_t usbFromHostISRBuf[64];
extern uint32_t usbFromHostISRBufLen;
EventGroupHandle_t usbToHostEventGroupHandle;
EventGroupHandle_t adcEventGroupHandle;
EventGroupHandle_t extiEventGroupHandle;
EventGroupHandle_t spiEventGroupHandle;
EventGroupHandle_t loraEventGroupHandle;
EventGroupHandle_t controllerEventGroupHandle;
EventGroupHandle_t gpscomEventGroupHandle;
EventGroupHandle_t sensorsEventGroupHandle;

/* USER CODE END Variables */
osThreadId defaultTaskHandle;
osThreadId usbToHostTaskHandle;
osThreadId usbFromHostTaskHandle;
osThreadId controllerTaskHandle;
osThreadId interpreterTaskHandle;
osThreadId loraTaskHandle;
osThreadId gpscomTaskHandle;
osThreadId sensorsTaskHandle;
osMessageQId usbToHostQueueHandle;
osMessageQId usbFromHostQueueHandle;
osMessageQId loraInQueueHandle;
osMessageQId loraOutQueueHandle;
osMessageQId loraMacQueueHandle;
osMessageQId gpscomInQueueHandle;
osMessageQId gpscomOutQueueHandle;
osMessageQId sensorsOutQueueHandle;
osMessageQId sensorsInQueueHandle;
osMessageQId interOutQueueHandle;
osTimerId controllerSendTimerHandle;
osTimerId gpscomtRXTimerHandle;
osMutexId gpscomCtxMutexHandle;
osMutexId trackMeApplUpDataMutexHandle;
osMutexId trackMeApplDnDataMutexHandle;
osSemaphoreId usbToHostBinarySemHandle;

void StartDefaultTask(void const * argument);
void StartUsbToHostTask(void const * argument);
void StartUsbFromHostTask(void const * argument);
void StartControllerTask(void const * argument);
void StartInterpreterTask(void const * argument);
void StartLoraTask(void const * argument);
void StartGpscomTask(void const * argument);
void StartSensorsTask(void const * argument);
void controllerSendTimerCallback(void const * argument);
void gpscomtRXTimerCallback(void const * argument);

extern void MX_USB_DEVICE_Init(void);
void MX_FREERTOS_Init(void); /* (MISRA C 2004 rule 8.1) */

/* Hook prototypes */
void configureTimerForRunTimeStats(void);
unsigned long getRunTimeCounterValue(void);
void vApplicationIdleHook(void);
void vApplicationStackOverflowHook(TaskHandle_t xTask, signed char *pcTaskName);
void vApplicationMallocFailedHook(void);

/* USER CODE BEGIN 1 */
/* Functions needed when configGENERATE_RUN_TIME_STATS is on */
__weak void configureTimerForRunTimeStats(void)
{
}

__weak unsigned long getRunTimeCounterValue(void)
{
  return 0;
}
/* USER CODE END 1 */

/* USER CODE BEGIN 2 */
__weak void vApplicationIdleHook( void )
{
   /* vApplicationIdleHook() will only be called if configUSE_IDLE_HOOK is set
   to 1 in FreeRTOSConfig.h. It will be called on each iteration of the idle
   task. It is essential that code added to this hook function never attempts
   to block in any way (for example, call xQueueReceive() with a block time
   specified, or call vTaskDelay()). If the application makes use of the
   vTaskDelete() API function (as this demo application does) then it is also
   important that vApplicationIdleHook() is permitted to return to its calling
   function, because it is the responsibility of the idle task to clean up
   memory allocated by the kernel to any task that has since been deleted. */
}
/* USER CODE END 2 */

/* USER CODE BEGIN 4 */
__weak void vApplicationStackOverflowHook(TaskHandle_t xTask, signed char *pcTaskName)
{
   /* Run time stack overflow checking is performed if
   configCHECK_FOR_STACK_OVERFLOW is defined to 1 or 2. This hook function is
   called if a stack overflow is detected. */
}
/* USER CODE END 4 */

/* USER CODE BEGIN 5 */
__weak void vApplicationMallocFailedHook(void)
{
   /* vApplicationMallocFailedHook() will only be called if
   configUSE_MALLOC_FAILED_HOOK is set to 1 in FreeRTOSConfig.h. It is a hook
   function that will get called if a call to pvPortMalloc() fails.
   pvPortMalloc() is called internally by the kernel whenever a task, queue,
   timer or semaphore is created. It is also called by various parts of the
   demo application. If heap_1.c or heap_2.c are used, then the size of the
   heap available to pvPortMalloc() is defined by configTOTAL_HEAP_SIZE in
   FreeRTOSConfig.h, and the xPortGetFreeHeapSize() API function can be used
   to query the size of free heap space that remains (although it does not
   provide information on how the remaining heap might be fragmented). */
}
/* USER CODE END 5 */

void MX_FREERTOS_Init(void) {

  /* Create the mutex(es) */
  /* definition and creation of gpscomCtxMutex */
  osMutexDef(gpscomCtxMutex);
  gpscomCtxMutexHandle = osMutexCreate(osMutex(gpscomCtxMutex));

  /* definition and creation of trackMeApplUpDataMutex */
  osMutexDef(trackMeApplUpDataMutex);
  trackMeApplUpDataMutexHandle = osMutexCreate(osMutex(trackMeApplUpDataMutex));

  /* definition and creation of trackMeApplDnDataMutex */
  osMutexDef(trackMeApplDnDataMutex);
  trackMeApplDnDataMutexHandle = osMutexCreate(osMutex(trackMeApplDnDataMutex));

  /* Create the semaphores(s) */
  /* definition and creation of usbToHostBinarySem */
  osSemaphoreDef(usbToHostBinarySem);
  usbToHostBinarySemHandle = osSemaphoreCreate(osSemaphore(usbToHostBinarySem), 1);

  /* USER CODE BEGIN RTOS_SEMAPHORES */
  /* add semaphores, ... */
  usbToHostEventGroupHandle = xEventGroupCreate();
  adcEventGroupHandle = xEventGroupCreate();
  extiEventGroupHandle = xEventGroupCreate();
  spiEventGroupHandle = xEventGroupCreate();
  loraEventGroupHandle = xEventGroupCreate();
  controllerEventGroupHandle = xEventGroupCreate();
  gpscomEventGroupHandle = xEventGroupCreate();
  sensorsEventGroupHandle = xEventGroupCreate();
  /* USER CODE END RTOS_SEMAPHORES */

  /* Create the timer(s) */
  /* definition and creation of controllerSendTimer */
  osTimerDef(controllerSendTimer, controllerSendTimerCallback);
  controllerSendTimerHandle = osTimerCreate(osTimer(controllerSendTimer), osTimerPeriodic, NULL);

  /* definition and creation of gpscomtRXTimer */
  osTimerDef(gpscomtRXTimer, gpscomtRXTimerCallback);
  gpscomtRXTimerHandle = osTimerCreate(osTimer(gpscomtRXTimer), osTimerPeriodic, NULL);

  /* USER CODE BEGIN RTOS_TIMERS */
  /* start timers, add new ones, ... */
  vTimerSetTimerID(controllerSendTimerHandle, "controllerSendTmr");
  vTimerSetTimerID(gpscomtRXTimerHandle, "gpscomRXTmr");

  /* USER CODE END RTOS_TIMERS */

  /* Create the queue(s) */
  /* definition and creation of usbToHostQueue */
  osMessageQDef(usbToHostQueue, 512, uint8_t);
  usbToHostQueueHandle = osMessageCreate(osMessageQ(usbToHostQueue), NULL);

  /* definition and creation of usbFromHostQueue */
  osMessageQDef(usbFromHostQueue, 32, uint8_t);
  usbFromHostQueueHandle = osMessageCreate(osMessageQ(usbFromHostQueue), NULL);

  /* definition and creation of loraInQueue */
  osMessageQDef(loraInQueue, 256, uint8_t);
  loraInQueueHandle = osMessageCreate(osMessageQ(loraInQueue), NULL);

  /* definition and creation of loraOutQueue */
  osMessageQDef(loraOutQueue, 8, uint8_t);
  loraOutQueueHandle = osMessageCreate(osMessageQ(loraOutQueue), NULL);

  /* definition and creation of loraMacQueue */
  osMessageQDef(loraMacQueue, 32, uint8_t);
  loraMacQueueHandle = osMessageCreate(osMessageQ(loraMacQueue), NULL);

  /* definition and creation of gpscomInQueue */
  osMessageQDef(gpscomInQueue, 64, uint8_t);
  gpscomInQueueHandle = osMessageCreate(osMessageQ(gpscomInQueue), NULL);

  /* definition and creation of gpscomOutQueue */
  osMessageQDef(gpscomOutQueue, 8, uint8_t);
  gpscomOutQueueHandle = osMessageCreate(osMessageQ(gpscomOutQueue), NULL);

  /* definition and creation of sensorsOutQueue */
  osMessageQDef(sensorsOutQueue, 32, uint8_t);
  sensorsOutQueueHandle = osMessageCreate(osMessageQ(sensorsOutQueue), NULL);

  /* definition and creation of sensorsInQueue */
  osMessageQDef(sensorsInQueue, 8, uint8_t);
  sensorsInQueueHandle = osMessageCreate(osMessageQ(sensorsInQueue), NULL);

  /* definition and creation of interOutQueue */
  osMessageQDef(interOutQueue, 256, uint8_t);
  interOutQueueHandle = osMessageCreate(osMessageQ(interOutQueue), NULL);

  /* USER CODE BEGIN RTOS_QUEUES */
  /* add queues, ... */
  vQueueAddToRegistry(usbToHostQueueHandle,       "USBtoHostQ");
  vQueueAddToRegistry(usbToHostBinarySemHandle,   "USBtoHostBSem");
  vQueueAddToRegistry(usbFromHostQueueHandle,     "USBfromHostQ");
  vQueueAddToRegistry(loraInQueueHandle,          "loraInQ");
  vQueueAddToRegistry(loraOutQueueHandle,         "loraOutQ");
  vQueueAddToRegistry(loraMacQueueHandle,         "loraMacQ");
  vQueueAddToRegistry(gpscomInQueueHandle,        "gpscomInQ");
  vQueueAddToRegistry(gpscomOutQueueHandle,       "gpscomOutQ");
  vQueueAddToRegistry(sensorsInQueueHandle,       "sensorsInQ");
  vQueueAddToRegistry(sensorsOutQueueHandle,      "sensorsOutQ");
  vQueueAddToRegistry(interOutQueueHandle,        "interOutQ");
  /* USER CODE END RTOS_QUEUES */

  /* Create the thread(s) */
  /* definition and creation of defaultTask */
  osThreadDef(defaultTask, StartDefaultTask, osPriorityLow, 0, 128);
  defaultTaskHandle = osThreadCreate(osThread(defaultTask), NULL);

  /* definition and creation of usbToHostTask */
  osThreadDef(usbToHostTask, StartUsbToHostTask, osPriorityAboveNormal, 0, 128);
  usbToHostTaskHandle = osThreadCreate(osThread(usbToHostTask), NULL);

  /* definition and creation of usbFromHostTask */
  osThreadDef(usbFromHostTask, StartUsbFromHostTask, osPriorityAboveNormal, 0, 128);
  usbFromHostTaskHandle = osThreadCreate(osThread(usbFromHostTask), NULL);

  /* definition and creation of controllerTask */
  osThreadDef(controllerTask, StartControllerTask, osPriorityNormal, 0, 1024);
  controllerTaskHandle = osThreadCreate(osThread(controllerTask), NULL);

  /* definition and creation of interpreterTask */
  osThreadDef(interpreterTask, StartInterpreterTask, osPriorityNormal, 0, 512);
  interpreterTaskHandle = osThreadCreate(osThread(interpreterTask), NULL);

  /* definition and creation of loraTask */
  osThreadDef(loraTask, StartLoraTask, osPriorityHigh, 0, 2048);
  loraTaskHandle = osThreadCreate(osThread(loraTask), NULL);

  /* definition and creation of gpscomTask */
  osThreadDef(gpscomTask, StartGpscomTask, osPriorityRealtime, 0, 1024);
  gpscomTaskHandle = osThreadCreate(osThread(gpscomTask), NULL);

  /* definition and creation of sensorsTask */
  osThreadDef(sensorsTask, StartSensorsTask, osPriorityAboveNormal, 0, 128);
  sensorsTaskHandle = osThreadCreate(osThread(sensorsTask), NULL);

}

void StartDefaultTask(void const * argument)
{
  /* init code for USB_DEVICE */
  MX_USB_DEVICE_Init();

  /* USER CODE BEGIN StartDefaultTask */
  mainDefaultTaskInit();

  /* Infinite loop */
  for (;;) {
    mainDefaultTaskLoop();
  }
  /* USER CODE END StartDefaultTask */
}

void StartUsbToHostTask(void const * argument)
{
  /* USER CODE BEGIN StartUsbToHostTask */

  /* Give DefaultTask time to prepare the device */
  osDelay(100);

  usbUsbToHostTaskInit();

  /* Infinite loop */
  for (;;) {
    usbUsbToHostTaskLoop();
  }
  /* USER CODE END StartUsbToHostTask */
}

void StartUsbFromHostTask(void const * argument)
{
  /* USER CODE BEGIN StartUsbFromHostTask */

  /* Give DefaultTask time to prepare the device */
  osDelay(100);

  usbUsbFromHostTaskInit();

  /* Infinite loop */
  for (;;) {
    usbUsbFromHostTaskLoop();
  }
  /* USER CODE END StartUsbFromHostTask */
}

void StartControllerTask(void const * argument)
{
  /* USER CODE BEGIN StartControllerTask */

  /* Give DefaultTask time to prepare the device */
  osDelay(100);

  controllerControllerTaskInit();

  /* Infinite loop */
  for(;;)
  {
    controllerControllerTaskLoop();
  }
  /* USER CODE END StartControllerTask */
}

void StartInterpreterTask(void const * argument)
{
  /* USER CODE BEGIN StartInterpreterTask */

  /* Give DefaultTask time to prepare the device */
  osDelay(100);

  interpreterInterpreterTaskInit();

  /* Infinite loop */
  for(;;)
  {
    interpreterInterpreterTaskLoop();
  }
  /* USER CODE END StartInterpreterTask */
}

void StartLoraTask(void const * argument)
{
  /* USER CODE BEGIN StartLoraTask */

  /* Give DefaultTask time to prepare the device */
  osDelay(100);

  loRaWANLoraTaskInit();

  /* Infinite loop */
  for(;;)
  {
    loRaWANLoraTaskLoop();
  }
  /* USER CODE END StartLoraTask */
}

void StartGpscomTask(void const * argument)
{
  /* USER CODE BEGIN StartGpscomTask */

  /* Give DefaultTask time to prepare the device */
  osDelay(100);

  gpscomGpscomTaskInit();

  /* Infinite loop */
  for(;;)
  {
    gpscomGpscomTaskLoop();
  }
  /* USER CODE END StartGpscomTask */
}

void StartSensorsTask(void const * argument)
{
  /* USER CODE BEGIN StartSensorsTask */

  /* Give DefaultTask time to prepare the device */
  osDelay(100);

  sensorsSensorsTaskInit();

  /* Infinite loop */
  for(;;)
  {
    sensorsSensorsTaskLoop();
  }
  /* USER CODE END StartSensorsTask */
}

/* controllerSendTimerCallback function */
void controllerSendTimerCallback(void const * argument)
{
  /* USER CODE BEGIN controllerSendTimerCallback */
  controllerSendTimerCallbackImpl((TimerHandle_t) argument);
  /* USER CODE END controllerSendTimerCallback */
}

/* gpscomtRXTimerCallback function */
void gpscomtRXTimerCallback(void const * argument)
{
  /* USER CODE BEGIN gpscomtRXTimerCallback */
  gpscomtRXTimerCallbackImpl((TimerHandle_t) argument);
  /* USER CODE END gpscomtRXTimerCallback */
}

/************************ (C) COPYRIGHT STMicroelectronics *****END OF FILE****/
